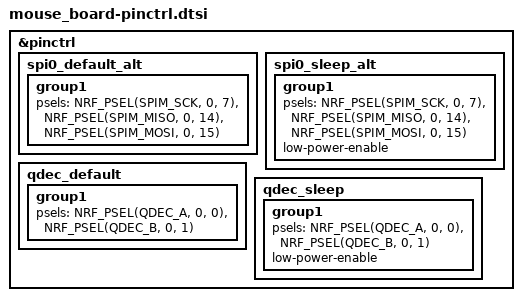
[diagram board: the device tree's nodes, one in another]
/*
 * Copyright (c) 2022 Nordic Semiconductor
 * SPDX-License-Identifier: Apache-2.0
 */

&pinctrl {

	spi0_default_alt: spi0_default_alt {
		group1 {
			psels = <NRF_PSEL(SPIM_SCK, 0, 7)>,
				<NRF_PSEL(SPIM_MISO, 0, 14)>,
				<NRF_PSEL(SPIM_MOSI, 0, 15)>;
		};
	};

	spi0_sleep_alt: spi0_sleep_alt {
		group1 {
			psels = <NRF_PSEL(SPIM_SCK, 0, 7)>,
				<NRF_PSEL(SPIM_MISO, 0, 14)>,
				<NRF_PSEL(SPIM_MOSI, 0, 15)>;
			low-power-enable;
		};
	};
	
	qdec_default: qdec_default {
		group1 {
			psels = <NRF_PSEL(QDEC_A, 0, 0)>,
				<NRF_PSEL(QDEC_B, 0, 1)>;
		};
	};

	qdec_sleep: qdec_sleep {
		group1 {
			psels = <NRF_PSEL(QDEC_A, 0, 0)>,
				<NRF_PSEL(QDEC_B, 0, 1)>;
			low-power-enable;
		};
	};
};
